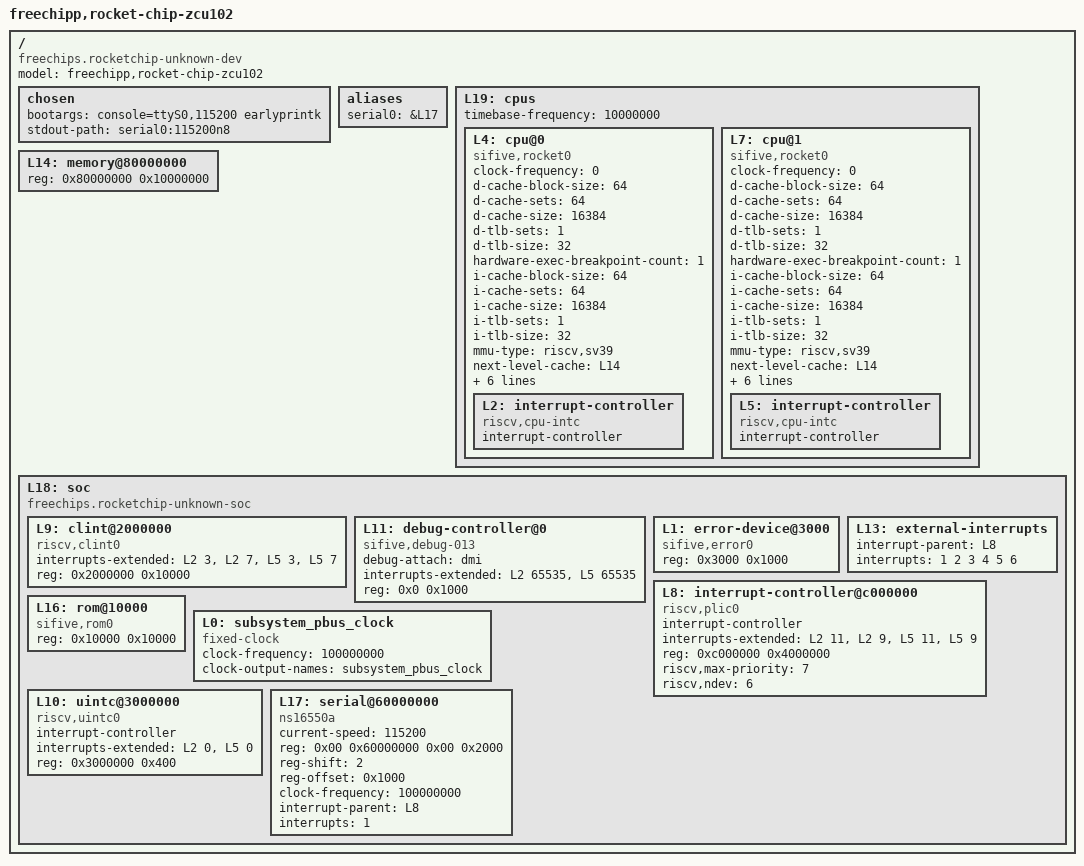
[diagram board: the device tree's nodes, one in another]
/dts-v1/;

/ {
	#address-cells = <1>;
	#size-cells = <1>;
	compatible = "freechips.rocketchip-unknown-dev";
	model = "freechipp,rocket-chip-zcu102";

	chosen {
		bootargs = "console=ttyS0,115200 earlyprintk";
		stdout-path = "serial0:115200n8";
	};

	aliases {
		serial0 = &L17;
	};

	L19: cpus {
		#address-cells = <1>;
		#size-cells = <0>;
		timebase-frequency = <10000000>;
		L4: cpu@0 {
			clock-frequency = <0>;
			compatible = "sifive,rocket0", "riscv";
			d-cache-block-size = <64>;
			d-cache-sets = <64>;
			d-cache-size = <16384>;
			d-tlb-sets = <1>;
			d-tlb-size = <32>;
			device_type = "cpu";
			hardware-exec-breakpoint-count = <1>;
			i-cache-block-size = <64>;
			i-cache-sets = <64>;
			i-cache-size = <16384>;
			i-tlb-sets = <1>;
			i-tlb-size = <32>;
			mmu-type = "riscv,sv39";
			next-level-cache = <&L14>;
			reg = <0x0>;
			riscv,isa = "rv64imafdc";
			riscv,pmpgranularity = <4>;
			riscv,pmpregions = <8>;
			status = "okay";
			timebase-frequency = <10000000>;
			tlb-split;
			L2: interrupt-controller {
				#interrupt-cells = <1>;
				compatible = "riscv,cpu-intc";
				interrupt-controller;
			};
		};
		L7: cpu@1 {
			clock-frequency = <0>;
			compatible = "sifive,rocket0", "riscv";
			d-cache-block-size = <64>;
			d-cache-sets = <64>;
			d-cache-size = <16384>;
			d-tlb-sets = <1>;
			d-tlb-size = <32>;
			device_type = "cpu";
			hardware-exec-breakpoint-count = <1>;
			i-cache-block-size = <64>;
			i-cache-sets = <64>;
			i-cache-size = <16384>;
			i-tlb-sets = <1>;
			i-tlb-size = <32>;
			mmu-type = "riscv,sv39";
			next-level-cache = <&L14>;
			reg = <0x1>;
			riscv,isa = "rv64imafdc";
			riscv,pmpgranularity = <4>;
			riscv,pmpregions = <8>;
			status = "okay";
			timebase-frequency = <10000000>;
			tlb-split;
			L5: interrupt-controller {
				#interrupt-cells = <1>;
				compatible = "riscv,cpu-intc";
				interrupt-controller;
			};
		};
	};
	L14: memory@80000000 {
		device_type = "memory";
		reg = <0x80000000 0x10000000>;
	};
	L18: soc {
		#address-cells = <1>;
		#size-cells = <1>;
		compatible = "freechips.rocketchip-unknown-soc", "simple-bus";
		ranges;
		L9: clint@2000000 {
			compatible = "riscv,clint0";
			interrupts-extended = <&L2 3 &L2 7 &L5 3 &L5 7>;
			reg = <0x2000000 0x10000>;
			reg-names = "control";
		};
		L11: debug-controller@0 {
			compatible = "sifive,debug-013", "riscv,debug-013";
			debug-attach = "dmi";
			interrupts-extended = <&L2 65535 &L5 65535>;
			reg = <0x0 0x1000>;
			reg-names = "control";
		};
		L1: error-device@3000 {
			compatible = "sifive,error0";
			reg = <0x3000 0x1000>;
		};
		L13: external-interrupts {
			interrupt-parent = <&L8>;
			interrupts = <1 2 3 4 5 6>;
		};
		L8: interrupt-controller@c000000 {
			#interrupt-cells = <1>;
			compatible = "riscv,plic0";
			interrupt-controller;
			interrupts-extended = <&L2 11 &L2 9 &L5 11 &L5 9>;
			reg = <0xc000000 0x4000000>;
			reg-names = "control";
			riscv,max-priority = <7>;
			riscv,ndev = <6>;
		};
		L16: rom@10000 {
			compatible = "sifive,rom0";
			reg = <0x10000 0x10000>;
			reg-names = "mem";
		};
		L0: subsystem_pbus_clock {
			#clock-cells = <0>;
			clock-frequency = <100000000>;
			clock-output-names = "subsystem_pbus_clock";
			compatible = "fixed-clock";
		};
		L10: uintc@3000000 {
			#interrupt-cells = <1>;
			compatible = "riscv,uintc0";
			interrupt-controller;
			interrupts-extended = <&L2 0 &L5 0>;
			reg = <0x3000000 0x400>;
			reg-names = "control";
		};
		L17: serial@60000000 {
			compatible = "ns16550a";
			current-speed = <115200>;
			reg = <0x00 0x60000000 0x00 0x2000>;
			reg-shift = <2>;
			reg-offset = <0x1000>;
			clock-frequency = <100000000>;
			interrupt-parent = <&L8>;
			interrupts = <1>;
		};
	};
};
